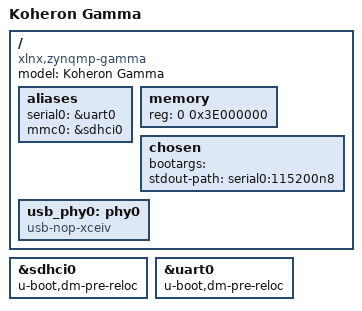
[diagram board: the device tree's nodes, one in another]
/*
 * Koheron Gamma devicetree
 *
 * Copyright (C) 2015, Xilinx, Inc.
 * Copyright (C) 2018 Koheron SAS
 *
 * SPDX-License-Identifier:	GPL-2.0+
 */
/dts-v1/;

#include "zynqmp.dtsi"
#include "zynqmp-clk-ccf.dtsi"
#include <dt-bindings/gpio/gpio.h>
#include <dt-bindings/pinctrl/pinctrl-zynqmp.h>
#include <dt-bindings/phy/phy.h>


/ {
	model = "Koheron Gamma";
	compatible = "xlnx,zynqmp-gamma","xlnx,zynqmp";

	aliases {
		serial0 = &uart0;
        mmc0 = &sdhci0;
	};

	memory {
		device_type = "memory";
		reg = <0 0x3E000000>;
	};

	chosen {
		bootargs = "";
		stdout-path = "serial0:115200n8";
	};

	usb_phy0: phy0 {
		compatible = "usb-nop-xceiv";
		#phy-cells = <0>;
	};

};

&sdhci0 {
	u-boot,dm-pre-reloc;
	status = "okay";
};

&uart0 {
	u-boot,dm-pre-reloc;
	status = "okay";
};
